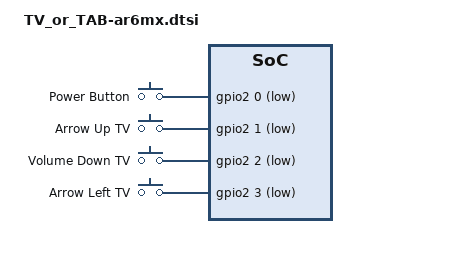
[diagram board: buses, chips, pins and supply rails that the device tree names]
/{
        gpio-keys {
                compatible = "gpio-keys";

                power-button {
                        label = "Power Button";
                        gpios = <&gpio2 0 GPIO_ACTIVE_LOW>;
                        linux,code = <116>; /* KEY_POWER*/
                        gpio-key,wakeup;
                        linux,input-type=<1>; /* EV_KEY, default, but included for completeness */
                };  

                arrow-up-tv {
                        label = "Arrow Up TV";
                        gpios = <&gpio2 1 GPIO_ACTIVE_LOW>;
                        linux,code = <186>; /* KEY_F16 */
                        linux,input-type=<0>; /* EV_SYN */
                };  


                volume-down-tv {
                        label = "Volume Down TV";
                        gpios = <&gpio2 2 GPIO_ACTIVE_LOW>;
                        linux,code = <187>;  /* KEY_F17 */
                        linux,input-type=<0>; /* EV_SYN */
                };  

                arrow-left-tv {
                        label = "Arrow Left TV";
                        gpios = <&gpio2 3 GPIO_ACTIVE_LOW>;
                        linux,code = <188>; /* KEY_F18 */
                        linux,input-type=<0>; /* EV_SYN */
                };  

        };
};
